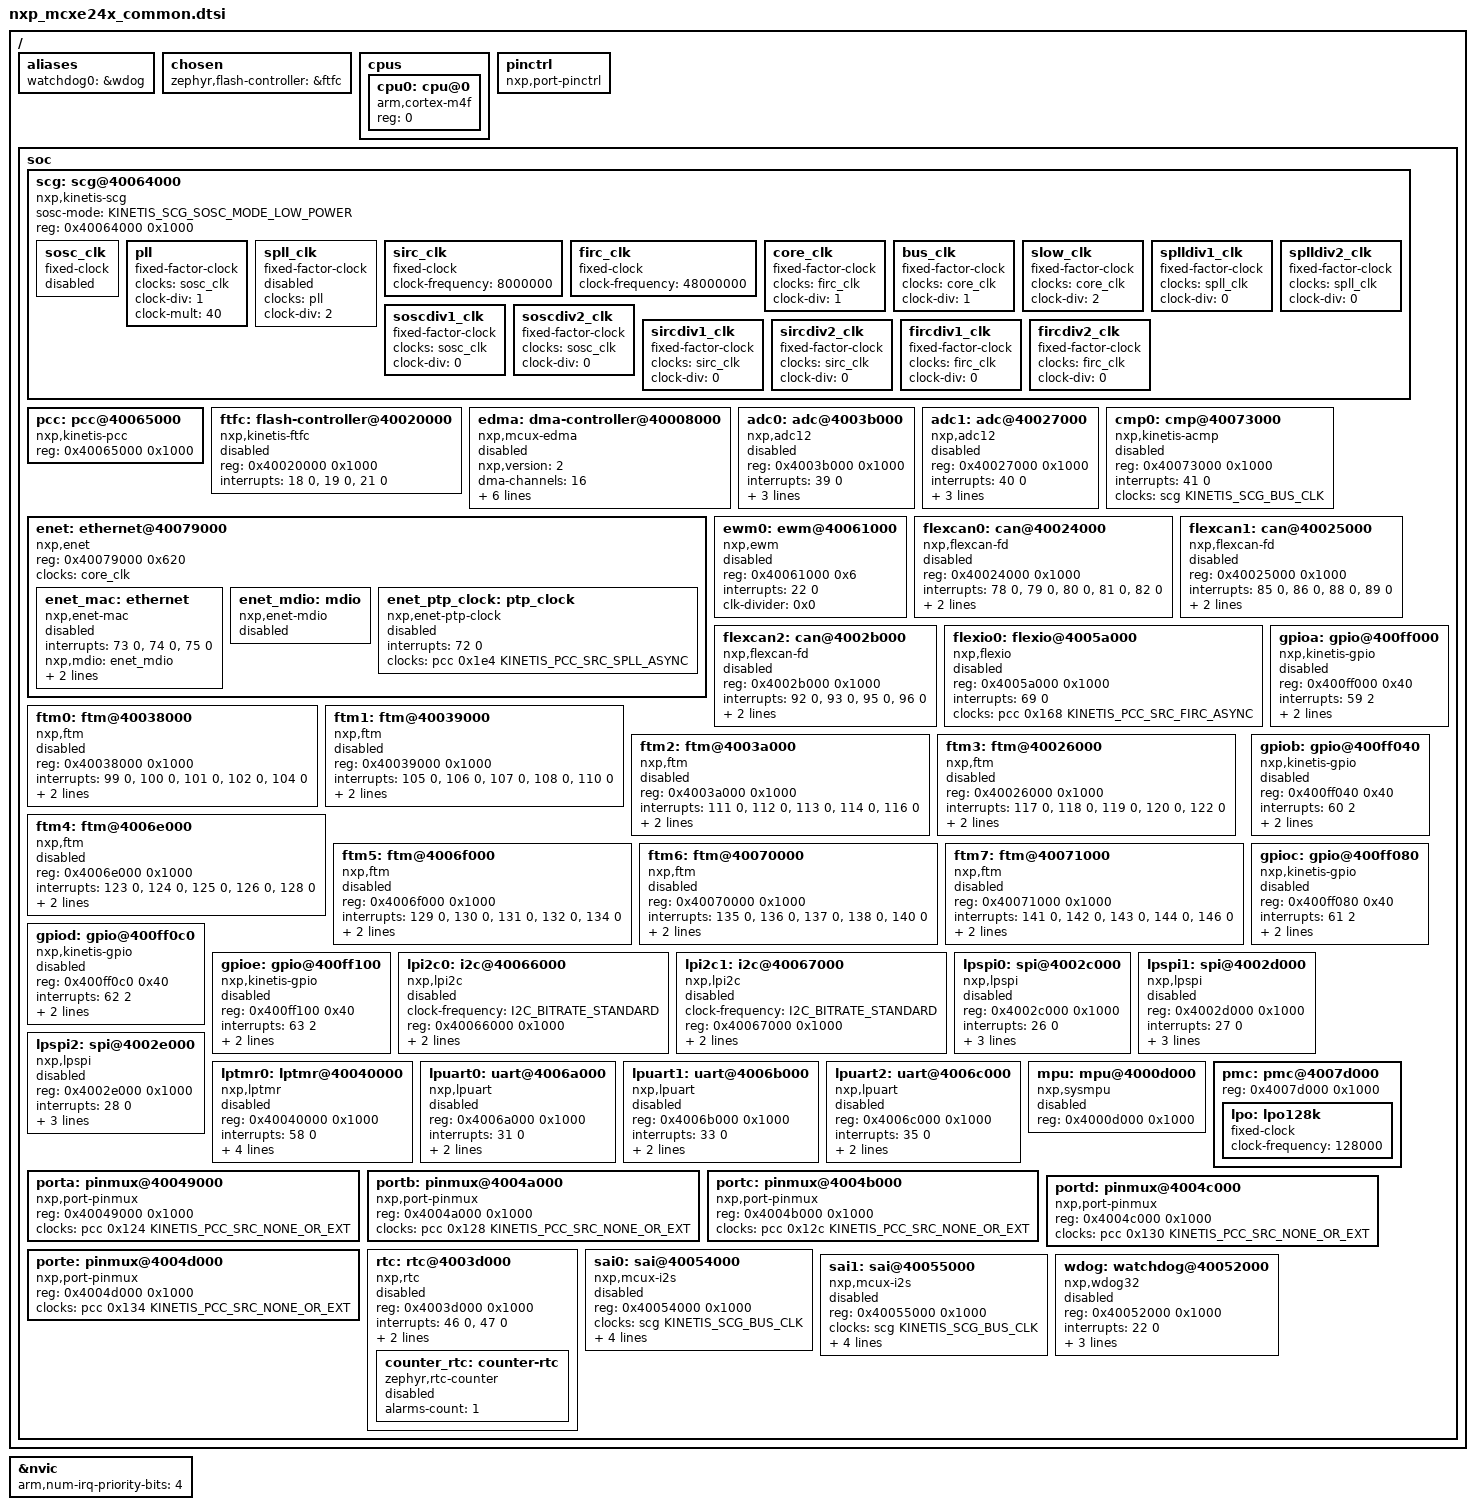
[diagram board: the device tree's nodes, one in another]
/*
 * Copyright 2025 NXP
 *
 * SPDX-License-Identifier: Apache-2.0
 */

#include <arm/armv7-m.dtsi>
#include <zephyr/dt-bindings/adc/adc.h>
#include <zephyr/dt-bindings/clock/kinetis_pcc.h>
#include <zephyr/dt-bindings/clock/kinetis_scg.h>
#include <zephyr/dt-bindings/gpio/gpio.h>
#include <zephyr/dt-bindings/i2c/i2c.h>

/ {
	aliases {
		watchdog0 = &wdog;
	};

	chosen {
		zephyr,flash-controller = &ftfc;
	};

	cpus {
		#address-cells = <1>;
		#size-cells = <0>;

		cpu0: cpu@0 {
			device_type = "cpu";
			compatible = "arm,cortex-m4f";
			reg = <0>;
		};
	};

	/* Dummy pinctrl node, filled with pin mux options at board level */
	pinctrl: pinctrl {
		compatible = "nxp,port-pinctrl";
		status = "okay";
	};

	soc {
		scg: scg@40064000 {
			compatible = "nxp,kinetis-scg";
			sosc-mode = <KINETIS_SCG_SOSC_MODE_LOW_POWER>;
			reg = <0x40064000 0x1000>;
			#clock-cells = <1>;

			sosc_clk: sosc_clk {
				compatible = "fixed-clock";
				#clock-cells = <0>;
				status = "disabled";
			};

			pll: pll {
				compatible = "fixed-factor-clock";
				clocks = <&sosc_clk>;
				clock-div = <1>;
				clock-mult = <40>;
				#clock-cells = <0>;
			};

			spll_clk: spll_clk {
				compatible = "fixed-factor-clock";
				clocks = <&pll>;
				clock-div = <2>;
				#clock-cells = <0>;
				status = "disabled";
			};

			sirc_clk: sirc_clk {
				compatible = "fixed-clock";
				clock-frequency = <8000000>;
				#clock-cells = <0>;
			};

			firc_clk: firc_clk {
				compatible = "fixed-clock";
				clock-frequency = <48000000>;
				#clock-cells = <0>;
			};

			core_clk: core_clk {
				compatible = "fixed-factor-clock";
				clocks = <&firc_clk>;
				clock-div = <1>;
				#clock-cells = <0>;
			};

			bus_clk: bus_clk {
				compatible = "fixed-factor-clock";
				clocks = <&core_clk>;
				clock-div = <1>;
				#clock-cells = <0>;
			};

			slow_clk: slow_clk {
				compatible = "fixed-factor-clock";
				clocks = <&core_clk>;
				clock-div = <2>;
				#clock-cells = <0>;
			};

			splldiv1_clk: splldiv1_clk {
				compatible = "fixed-factor-clock";
				clocks = <&spll_clk>;
				clock-div = <0>;
				#clock-cells = <0>;
			};

			splldiv2_clk: splldiv2_clk {
				compatible = "fixed-factor-clock";
				clocks = <&spll_clk>;
				clock-div = <0>;
				#clock-cells = <0>;
			};

			soscdiv1_clk: soscdiv1_clk {
				compatible = "fixed-factor-clock";
				clocks = <&sosc_clk>;
				clock-div = <0>;
				#clock-cells = <0>;
			};

			soscdiv2_clk: soscdiv2_clk {
				compatible = "fixed-factor-clock";
				clocks = <&sosc_clk>;
				clock-div = <0>;
				#clock-cells = <0>;
			};

			sircdiv1_clk: sircdiv1_clk {
				compatible = "fixed-factor-clock";
				clocks = <&sirc_clk>;
				clock-div = <0>;
				#clock-cells = <0>;
			};

			sircdiv2_clk: sircdiv2_clk {
				compatible = "fixed-factor-clock";
				clocks = <&sirc_clk>;
				clock-div = <0>;
				#clock-cells = <0>;
			};

			fircdiv1_clk: fircdiv1_clk {
				compatible = "fixed-factor-clock";
				clocks = <&firc_clk>;
				clock-div = <0>;
				#clock-cells = <0>;
			};

			fircdiv2_clk: fircdiv2_clk {
				compatible = "fixed-factor-clock";
				clocks = <&firc_clk>;
				clock-div = <0>;
				#clock-cells = <0>;
			};
		};

		pcc: pcc@40065000 {
			compatible = "nxp,kinetis-pcc";
			reg = <0x40065000 0x1000>;
			#clock-cells = <2>;
		};

		ftfc: flash-controller@40020000 {
			compatible = "nxp,kinetis-ftfc";
			reg = <0x40020000 0x1000>;
			interrupts = <18 0>, <19 0>, <21 0>;
			interrupt-names = "command-complete", "read-collision", "double-bit";
			#address-cells = <1>;
			#size-cells = <1>;
			status = "disabled";
		};

		edma: dma-controller@40008000 {
			compatible = "nxp,mcux-edma";
			nxp,version = <2>;
			dma-channels = <16>;
			dma-requests = <64>;
			nxp,mem2mem;
			reg = <0x40008000 0x1000>, <0x40021000 0x1000>;
			interrupts = <0 0>, <1 0>, <2 0>, <3 0>,
				     <4 0>, <5 0>, <6 0>, <7 0>,
				     <8 0>, <9 0>, <10 0>, <11 0>,
				     <12 0>, <13 0>, <14 0>, <15 0>,
				     <16 0>;
			#dma-cells = <2>;
			status = "disabled";
		};

		adc0: adc@4003b000 {
			compatible = "nxp,adc12";
			reg = <0x4003b000 0x1000>;
			interrupts = <39 0>;
			clocks = <&pcc 0xec KINETIS_PCC_SRC_FIRC_ASYNC>;
			clk-source = <0>;
			clk-divider = <1>;
			#io-channel-cells = <1>;
			status = "disabled";
		};

		adc1: adc@40027000 {
			compatible = "nxp,adc12";
			reg = <0x40027000 0x1000>;
			interrupts = <40 0>;
			clocks = <&pcc 0x9c KINETIS_PCC_SRC_FIRC_ASYNC>;
			clk-source = <0>;
			clk-divider = <1>;
			#io-channel-cells = <1>;
			status = "disabled";
		};

		cmp0: cmp@40073000 {
			compatible = "nxp,kinetis-acmp";
			reg = <0x40073000 0x1000>;
			interrupts = <41 0>;
			clocks = <&scg KINETIS_SCG_BUS_CLK>;
			status = "disabled";
		};

		enet: ethernet@40079000 {
			compatible = "nxp,enet";
			reg = <0x40079000 0x620>;
			clocks = <&core_clk>;

			enet_mac: ethernet {
				compatible = "nxp,enet-mac";
				interrupts = <73 0>, <74 0>, <75 0>;
				interrupt-names = "TX", "RX", "ERR";
				nxp,mdio = <&enet_mdio>;
				ptp-clock = <&enet_ptp_clock>;
				phy-connection-type = "rmii";
				status = "disabled";
			};

			enet_mdio: mdio {
				compatible = "nxp,enet-mdio";
				#address-cells = <1>;
				#size-cells = <0>;
				status = "disabled";
			};

			enet_ptp_clock: ptp_clock {
				compatible = "nxp,enet-ptp-clock";
				interrupts = <72 0>;
				interrupt-names = "IEEE1588_TMR";
				clocks = <&pcc 0x1e4 KINETIS_PCC_SRC_SPLL_ASYNC>;
				status = "disabled";
			};
		};

		ewm0: ewm@40061000 {
			compatible = "nxp,ewm";
			reg = <0x40061000 0x6>;
			interrupts = <22 0>;
			clk-divider = <0x0>;
			status = "disabled";
		};

		flexcan0: can@40024000 {
			compatible = "nxp,flexcan-fd", "nxp,flexcan";
			reg = <0x40024000 0x1000>;
			interrupts = <78 0>, <79 0>, <80 0>, <81 0>, <82 0>;
			interrupt-names = "ored-warning-bus-off", "error", "wake-up",
					  "mb-0-15", "mb-16-31";
			clocks = <&scg KINETIS_SCG_CORESYS_CLK>;
			clk-source = <0>;
			status = "disabled";
		};

		flexcan1: can@40025000 {
			compatible = "nxp,flexcan-fd", "nxp,flexcan";
			reg = <0x40025000 0x1000>;
			interrupts = <85 0>, <86 0>, <88 0>, <89 0>;
			interrupt-names = "ored-warning-bus-off", "error", "mb-0-15", "mb-16-31";
			clocks = <&scg KINETIS_SCG_CORESYS_CLK>;
			clk-source = <0>;
			status = "disabled";
		};

		flexcan2: can@4002b000 {
			compatible = "nxp,flexcan-fd", "nxp,flexcan";
			reg = <0x4002b000 0x1000>;
			interrupts = <92 0>, <93 0>, <95 0>, <96 0>;
			interrupt-names = "ored-warning-bus-off", "error", "mb-0-15", "mb-16-31";
			clocks = <&scg KINETIS_SCG_CORESYS_CLK>;
			clk-source = <0>;
			status = "disabled";
		};

		flexio0: flexio@4005a000 {
			compatible = "nxp,flexio";
			reg = <0x4005a000 0x1000>;
			interrupts = <69 0>;
			clocks = <&pcc 0x168 KINETIS_PCC_SRC_FIRC_ASYNC>;
			status = "disabled";
		};

		ftm0: ftm@40038000 {
			compatible = "nxp,ftm";
			reg = <0x40038000 0x1000>;
			interrupts = <99 0>, <100 0>, <101 0>, <102 0>, <104 0>;
			interrupt-names = "0-1", "2-3", "4-5", "6-7", "overflow";
			clocks = <&pcc 0xe0 KINETIS_PCC_SRC_FIRC_ASYNC>;
			prescaler = <1>;
			status = "disabled";
		};

		ftm1: ftm@40039000 {
			compatible = "nxp,ftm";
			reg = <0x40039000 0x1000>;
			interrupts = <105 0>, <106 0>, <107 0>, <108 0>, <110 0>;
			interrupt-names = "0-1", "2-3", "4-5", "6-7", "overflow";
			clocks = <&pcc 0xe4 KINETIS_PCC_SRC_FIRC_ASYNC>;
			prescaler = <1>;
			status = "disabled";
		};

		ftm2: ftm@4003a000 {
			compatible = "nxp,ftm";
			reg = <0x4003a000 0x1000>;
			interrupts = <111 0>, <112 0>, <113 0>, <114 0>, <116 0>;
			interrupt-names = "0-1", "2-3", "4-5", "6-7", "overflow";
			clocks = <&pcc 0xe8 KINETIS_PCC_SRC_FIRC_ASYNC>;
			prescaler = <1>;
			status = "disabled";
		};

		ftm3: ftm@40026000 {
			compatible = "nxp,ftm";
			reg = <0x40026000 0x1000>;
			interrupts = <117 0>, <118 0>, <119 0>, <120 0>, <122 0>;
			interrupt-names = "0-1", "2-3", "4-5", "6-7", "overflow";
			clocks = <&pcc 0x98 KINETIS_PCC_SRC_FIRC_ASYNC>;
			prescaler = <1>;
			status = "disabled";
		};

		ftm4: ftm@4006e000 {
			compatible = "nxp,ftm";
			reg = <0x4006e000 0x1000>;
			interrupts = <123 0>, <124 0>, <125 0>, <126 0>, <128 0>;
			interrupt-names = "0-1", "2-3", "4-5", "6-7", "overflow";
			clocks = <&pcc 0x1b8 KINETIS_PCC_SRC_FIRC_ASYNC>;
			prescaler = <1>;
			status = "disabled";
		};

		ftm5: ftm@4006f000 {
			compatible = "nxp,ftm";
			reg = <0x4006f000 0x1000>;
			interrupts = <129 0>, <130 0>, <131 0>, <132 0>, <134 0>;
			interrupt-names = "0-1", "2-3", "4-5", "6-7", "overflow";
			clocks = <&pcc 0x1bc KINETIS_PCC_SRC_FIRC_ASYNC>;
			prescaler = <1>;
			status = "disabled";
		};

		ftm6: ftm@40070000 {
			compatible = "nxp,ftm";
			reg = <0x40070000 0x1000>;
			interrupts = <135 0>, <136 0>, <137 0>, <138 0>, <140 0>;
			interrupt-names = "0-1", "2-3", "4-5", "6-7", "overflow";
			clocks = <&pcc 0x1c0 KINETIS_PCC_SRC_FIRC_ASYNC>;
			prescaler = <1>;
			status = "disabled";
		};

		ftm7: ftm@40071000 {
			compatible = "nxp,ftm";
			reg = <0x40071000 0x1000>;
			interrupts = <141 0>, <142 0>, <143 0>, <144 0>, <146 0>;
			interrupt-names = "0-1", "2-3", "4-5", "6-7", "overflow";
			clocks = <&pcc 0x1c4 KINETIS_PCC_SRC_FIRC_ASYNC>;
			prescaler = <1>;
			status = "disabled";
		};

		gpioa: gpio@400ff000 {
			compatible = "nxp,kinetis-gpio";
			reg = <0x400ff000 0x40>;
			interrupts = <59 2>;
			gpio-controller;
			#gpio-cells = <2>;
			nxp,kinetis-port = <&porta>;
			status = "disabled";
		};

		gpiob: gpio@400ff040 {
			compatible = "nxp,kinetis-gpio";
			reg = <0x400ff040 0x40>;
			interrupts = <60 2>;
			gpio-controller;
			#gpio-cells = <2>;
			nxp,kinetis-port = <&portb>;
			status = "disabled";
		};

		gpioc: gpio@400ff080 {
			compatible = "nxp,kinetis-gpio";
			reg = <0x400ff080 0x40>;
			interrupts = <61 2>;
			gpio-controller;
			#gpio-cells = <2>;
			nxp,kinetis-port = <&portc>;
			status = "disabled";
		};

		gpiod: gpio@400ff0c0 {
			compatible = "nxp,kinetis-gpio";
			reg = <0x400ff0c0 0x40>;
			interrupts = <62 2>;
			gpio-controller;
			#gpio-cells = <2>;
			nxp,kinetis-port = <&portd>;
			status = "disabled";
		};

		gpioe: gpio@400ff100 {
			compatible = "nxp,kinetis-gpio";
			reg = <0x400ff100 0x40>;
			interrupts = <63 2>;
			gpio-controller;
			#gpio-cells = <2>;
			nxp,kinetis-port = <&porte>;
			status = "disabled";
		};

		lpi2c0: i2c@40066000 {
			compatible = "nxp,lpi2c";
			clock-frequency = <I2C_BITRATE_STANDARD>;
			#address-cells = <1>;
			#size-cells = <0>;
			reg = <0x40066000 0x1000>;
			interrupts = <24 0>, <25 0>;
			interrupt-names = "controller", "target";
			clocks = <&pcc 0x198 KINETIS_PCC_SRC_FIRC_ASYNC>;
			status = "disabled";
		};

		lpi2c1: i2c@40067000 {
			compatible = "nxp,lpi2c";
			clock-frequency = <I2C_BITRATE_STANDARD>;
			#address-cells = <1>;
			#size-cells = <0>;
			reg = <0x40067000 0x1000>;
			interrupts = <29 0>, <30 0>;
			interrupt-names = "controller", "target";
			clocks = <&pcc 0x19c KINETIS_PCC_SRC_FIRC_ASYNC>;
			status = "disabled";
		};

		lpspi0: spi@4002c000 {
			compatible = "nxp,lpspi";
			reg = <0x4002c000 0x1000>;
			interrupts = <26 0>;
			clocks = <&pcc 0xb0 KINETIS_PCC_SRC_FIRC_ASYNC>;
			#address-cells = <1>;
			#size-cells = <0>;
			tx-fifo-size = <4>;
			rx-fifo-size = <4>;
			status = "disabled";
		};

		lpspi1: spi@4002d000 {
			compatible = "nxp,lpspi";
			reg = <0x4002d000 0x1000>;
			interrupts = <27 0>;
			clocks = <&pcc 0xb4 KINETIS_PCC_SRC_FIRC_ASYNC>;
			#address-cells = <1>;
			#size-cells = <0>;
			tx-fifo-size = <4>;
			rx-fifo-size = <4>;
			status = "disabled";
		};

		lpspi2: spi@4002e000 {
			compatible = "nxp,lpspi";
			reg = <0x4002e000 0x1000>;
			interrupts = <28 0>;
			clocks = <&pcc 0xb8 KINETIS_PCC_SRC_FIRC_ASYNC>;
			#address-cells = <1>;
			#size-cells = <0>;
			tx-fifo-size = <4>;
			rx-fifo-size = <4>;
			status = "disabled";
		};

		lptmr0: lptmr@40040000 {
			compatible = "nxp,lptmr";
			reg = <0x40040000 0x1000>;
			interrupts = <58 0>;
			clock-frequency = <1000>;
			prescale-glitch-filter = <0>;
			clk-source = <1>;
			resolution = <16>;
			status = "disabled";
		};

		lpuart0: uart@4006a000 {
			compatible = "nxp,lpuart";
			reg = <0x4006a000 0x1000>;
			interrupts = <31 0>;
			clocks = <&pcc 0x1a8 KINETIS_PCC_SRC_FIRC_ASYNC>;
			dmas = <&edma 0 2>, <&edma 1 3>;
			dma-names = "rx", "tx";
			status = "disabled";
		};

		lpuart1: uart@4006b000 {
			compatible = "nxp,lpuart";
			reg = <0x4006b000 0x1000>;
			interrupts = <33 0>;
			clocks = <&pcc 0x1ac KINETIS_PCC_SRC_FIRC_ASYNC>;
			dmas = <&edma 2 4>, <&edma 3 5>;
			dma-names = "rx", "tx";
			status = "disabled";
		};

		lpuart2: uart@4006c000 {
			compatible = "nxp,lpuart";
			reg = <0x4006c000 0x1000>;
			interrupts = <35 0>;
			clocks = <&pcc 0x1b0 KINETIS_PCC_SRC_FIRC_ASYNC>;
			dmas = <&edma 4 6>, <&edma 5 7>;
			dma-names = "rx", "tx";
			status = "disabled";
		};

		mpu: mpu@4000d000 {
			compatible = "nxp,sysmpu";
			reg = <0x4000d000 0x1000>;
			status = "disabled";
		};

		pmc: pmc@4007d000 {
			reg = <0x4007d000 0x1000>;

			lpo: lpo128k {
				compatible = "fixed-clock";
				clock-frequency = <128000>;
				#clock-cells = <0>;
			};
		};

		porta: pinmux@40049000 {
			compatible = "nxp,port-pinmux";
			reg = <0x40049000 0x1000>;
			clocks = <&pcc 0x124 KINETIS_PCC_SRC_NONE_OR_EXT>;
		};

		portb: pinmux@4004a000 {
			compatible = "nxp,port-pinmux";
			reg = <0x4004a000 0x1000>;
			clocks = <&pcc 0x128 KINETIS_PCC_SRC_NONE_OR_EXT>;
		};

		portc: pinmux@4004b000 {
			compatible = "nxp,port-pinmux";
			reg = <0x4004b000 0x1000>;
			clocks = <&pcc 0x12c KINETIS_PCC_SRC_NONE_OR_EXT>;
		};

		portd: pinmux@4004c000 {
			compatible = "nxp,port-pinmux";
			reg = <0x4004c000 0x1000>;
			clocks = <&pcc 0x130 KINETIS_PCC_SRC_NONE_OR_EXT>;
		};

		porte: pinmux@4004d000 {
			compatible = "nxp,port-pinmux";
			reg = <0x4004d000 0x1000>;
			clocks = <&pcc 0x134 KINETIS_PCC_SRC_NONE_OR_EXT>;
		};

		rtc: rtc@4003d000 {
			compatible = "nxp,rtc";
			reg = <0x4003d000 0x1000>;
			interrupts = <46 0>, <47 0>;
			interrupt-names = "alarm", "seconds";
			clock-frequency = <32768>;
			prescaler = <32768>;
			status = "disabled";

			counter_rtc: counter-rtc {
				compatible = "zephyr,rtc-counter";
				alarms-count = <1>;
				status = "disabled";
			};
		};

		sai0: sai@40054000 {
			compatible = "nxp,mcux-i2s";
			reg = <0x40054000 0x1000>;
			clocks = <&scg KINETIS_SCG_BUS_CLK>;
			interrupts = <70 0>, <71 0>;
			dmas = <&edma 6 60>, <&edma 7 61>;
			dma-names = "rx", "tx";
			nxp,rx-dma-channel = <6>;
			nxp,tx-dma-channel = <7>;
			#address-cells = <1>;
			#size-cells = <0>;
			#pinmux-cells = <2>;
			status = "disabled";
		};

		sai1: sai@40055000 {
			compatible = "nxp,mcux-i2s";
			reg = <0x40055000 0x1000>;
			clocks = <&scg KINETIS_SCG_BUS_CLK>;
			interrupts = <55 0>, <56 0>;
			dmas = <&edma 8 12>, <&edma 9 13>;
			dma-names = "rx", "tx";
			nxp,rx-dma-channel = <8>;
			nxp,tx-dma-channel = <9>;
			#address-cells = <1>;
			#size-cells = <0>;
			#pinmux-cells = <2>;
			status = "disabled";
		};

		wdog: watchdog@40052000 {
			compatible = "nxp,wdog32";
			reg = <0x40052000 0x1000>;
			interrupts = <22 0>;
			clocks = <&lpo>;
			clk-source = <1>;
			clk-divider = <256>;
			status = "disabled";
		};
	};
};

&nvic {
	arm,num-irq-priority-bits = <4>;
};
